# max32672 register map
Vendor: Maxim-Integrated; Series: ARMCM4; File version: 1.0
CPU: CM4 r2p1, little endian, MPU, FPU, 3 interrupt priority bits
Registers are 32-bit, read-write, reset 0x0 unless marked. A register's access mark holds for its fields unless they carry their own. Offsets are from the block's base; [hi:lo] are bit positions; 'fields as' and 'values as' point back to an identical list.

## TMR — Low-Power Configurable Timer
Base 0x40010000
Same registers: TMR1 0x40011000, TMR2 0x40012000, TMR3 0x40013000, TMR4 0x40114000, TMR5 0x40115000
0x00 CNT — Timer Counter Register.
  [31:0] COUNT — The current count value for the timer. This field increments as the timer counts.
0x04 CMP — Timer Compare Register.
  [31:0] COMPARE — The value in this register is used as the compare value for the timer's count value. The compare field meaning is determined by the specific mode of the timer.
0x08 PWM — Timer PWM Register.
  [31:0] PWM — Timer PWM Match: In PWM Mode, this field sets the count value for the first transition period of the PWM cycle. At the end of the cycle where CNT equals PWM, the PWM output transitions to the second period of the PWM cycle. The second PWM period count is stored in the CMP register. The value set for PWM must me less than the value set in CMP for PWM mode operation. Timer Capture Value: In Capture, Compare, and Capture/Compare modes, this field is used to store the CNT value when a Capture, Compare, or Capture/Compare event occurs.
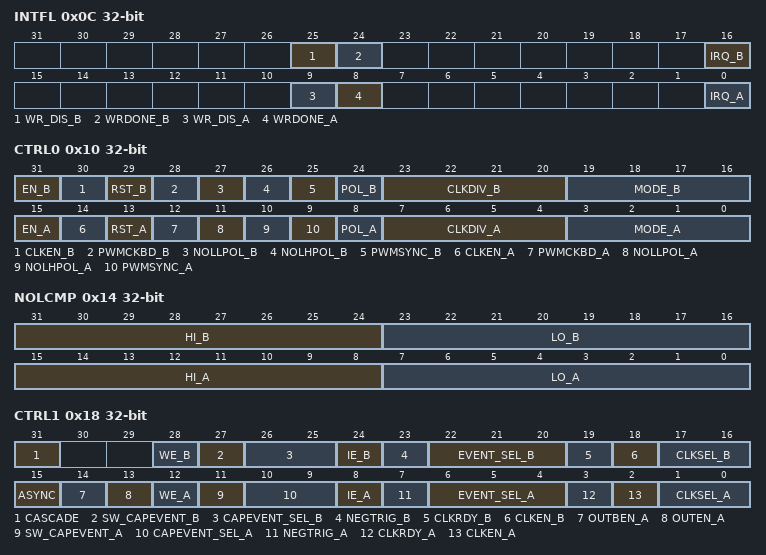
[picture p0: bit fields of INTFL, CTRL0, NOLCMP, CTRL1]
0x0C INTFL — Timer Interrupt Status Register.
  [25] WR_DIS_B — Write Disable to CNT/PWM for Timer B in the non-cascaded dual timer configuration.
  [24] WRDONE_B — Write Done Flag for Timer B indicating the write is complete from APB to CLK_TMR domain.
  [16] IRQ_B — Interrupt Flag for Timer B.
  [9] WR_DIS_A — Write Disable to CNT/PWM for Timer A in the non-cascaded dual timer configuration.
  [8] WRDONE_A — Write Done Flag for Timer A indicating the write is complete from APB to CLK_TMR domain.
  [0] IRQ_A — Interrupt Flag for Timer A.
0x10 CTRL0 — Timer Control Register.
  [31] EN_B — Enable for Timer B
  [30] CLKEN_B — Write 1 to Enable CLK_TMR for Timer B
  [29] RST_B — Resets all flip flops in the CLK_TMR domain for Timer B. Self-clears.
  [28] PWMCKBD_B — PWM Phase A-Prime Output Disable for Timer B
  [27] NOLLPOL_B — PWM Phase A-Prime (Non-Overlapping Low) Polarity for Timer B
  [26] NOLHPOL_B — PWM Phase A (Non-Overlapping High) Polarity for Timer B
  [25] PWMSYNC_B — PWM Synchronization Mode for Timer B
  [24] POL_B — Timer Polarity for Timer B
  [23:20] CLKDIV_B — Clock Divider Select for Timer B
    0=DIV_BY_1 (Prescaler Divide-By-1); 1=DIV_BY_2 (Prescaler Divide-By-2); 2=DIV_BY_4 (Prescaler Divide-By-4); 3=DIV_BY_8 (Prescaler Divide-By-8); 4=DIV_BY_16 (Prescaler Divide-By-16); 5=DIV_BY_32 (Prescaler Divide-By-32); 6=DIV_BY_64 (Prescaler Divide-By-64); 7=DIV_BY_128 (Prescaler Divide-By-128); 8=DIV_BY_256 (Prescaler Divide-By-256); 9=DIV_BY_512 (Prescaler Divide-By-512); 10=DIV_BY_1024 (Prescaler Divide-By-1024); 11=DIV_BY_2048 (Prescaler Divide-By-2048); 12=DIV_BY_4096
  [19:16] MODE_B — Mode Select for Timer B
    0=ONE_SHOT (One-Shot Mode); 1=CONTINUOUS (Continuous Mode); 2=COUNTER (Counter Mode); 3=PWM (PWM Mode); 4=CAPTURE (Capture Mode); 5=COMPARE (Compare Mode); 6=GATED (Gated Mode); 7=CAPCOMP (Capture/Compare Mode); 8=DUAL_EDGE (Dual Edge Capture Mode); 14=IGATED (Inactive Gated Mode)
  [15] EN_A — Enable for Timer A
  [14] CLKEN_A — Write 1 to Enable CLK_TMR for Timer A
  [13] RST_A — Resets all flip flops in the CLK_TMR domain for Timer A. Self-clears.
  [12] PWMCKBD_A — PWM Phase A-Prime Output Disable for Timer A
  [11] NOLLPOL_A — PWM Phase A-Prime (Non-Overlapping Low) Polarity for Timer A
  [10] NOLHPOL_A — PWM Phase A (Non-Overlapping High) Polarity for Timer A
  [9] PWMSYNC_A — PWM Synchronization Mode for Timer A
  [8] POL_A — Timer Polarity for Timer A
  [7:4] CLKDIV_A — Clock Divider Select for Timer A
    values as CLKDIV_B
  [3:0] MODE_A — Mode Select for Timer A
    0=ONE_SHOT (One-Shot Mode); 1=CONTINUOUS (Continuous Mode); 2=COUNTER (Counter Mode); 3=PWM (PWM Mode); 4=CAPTURE (Capture Mode); 5=COMPARE (Compare Mode); 6=GATED (Gated Mode); 7=CAPCOMP (Capture/Compare Mode); 8=DUAL_EDGE (Dual Edge Capture Mode); 12=IGATED (Inactive Gated Mode)
0x14 NOLCMP — Timer Non-Overlapping Compare Register.
  [31:24] HI_B — Non-Overlapping High Compare value for Timer B controls the time between the falling edge of PWM Phase A-Prime and the next rising edge of PWM Phase A.
  [23:16] LO_B — Non-Overlapping Low Compare value for Timer B controls the time between the falling edge of PWM Phase A and the next rising edge of PWM Phase A-Prime.
  [15:8] HI_A — Non-Overlapping High Compare value for Timer A controls the time between the falling edge of PWM Phase A-Prime and the next rising edge of PWM Phase A.
  [7:0] LO_A — Non-Overlapping Low Compare value for Timer A controls the time between the falling edge of PWM Phase A and the next rising edge of PWM Phase A-Prime.
0x18 CTRL1 — Timer Configuration Register.
  [31] CASCADE — Cascade two 16-bit timers into one 32-bit timer. Only available when C_TMR16=0 and C_DUALTMR16=1.
  [28] WE_B — Wake-Up Enable for Timer B
  [27] SW_CAPEVENT_B — Software Capture Event for Timer B
  [26:25] CAPEVENT_SEL_B — Capture Event Select for Timer B
  [24] IE_B — Interrupt Enable for Timer B
  [23] NEGTRIG_B — Negative Edge Trigger for Event for Timer B
  [22:20] EVENT_SEL_B — Event Select for Timer B
  [19] CLKRDY_B — CLK_TMR Ready Flag for Timer B
  [18] CLKEN_B — Timer B Enable Status
  [17:16] CLKSEL_B — Timer Clock Select for Timer B
  [15] ASYNC — Allows asynchronous reads to the PWM and CNT registers.
  [14] OUTBEN_A — PWM_CKB_EN_O Enable for Modes other than Mode 3 for Timer A
  [13] OUTEN_A — OUT_OE_O Enable for Modes 0, 1,and 5 for Timer A
  [12] WE_A — Wake-Up Enable for Timer A
  [11] SW_CAPEVENT_A — Software Capture Event for Timer A
  [10:9] CAPEVENT_SEL_A — Capture Event Select for Timer A
  [8] IE_A — Interrupt Enable for Timer A
  [7] NEGTRIG_A — Negative Edge Trigger for Event for Timer A
  [6:4] EVENT_SEL_A — Event Select for Timer A
  [3] CLKRDY_A — CLK_TMR Ready Flag for Timer A
  [2] CLKEN_A — Timer A Enable Status
  [1:0] CLKSEL_A — Timer Clock Select for Timer A
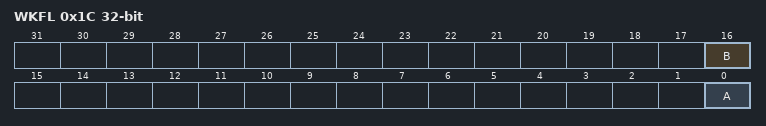
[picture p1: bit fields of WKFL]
0x1C WKFL — Timer Wakeup Status Register.
  [16] B — Wake-Up Flag for Timer B
  [0] A — Wake-Up Flag for Timer A
